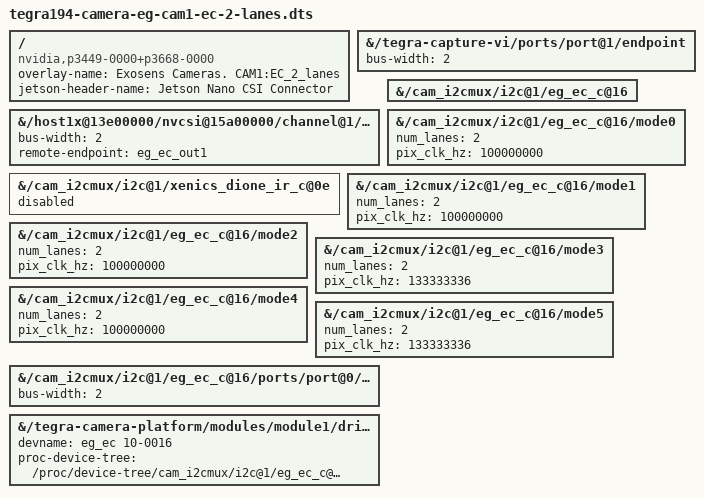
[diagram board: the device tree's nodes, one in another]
// SPDX-License-Identifier: GPL-2.0-only


/dts-v1/;
/plugin/;

/ {
	overlay-name = "Exosens Cameras. CAM1:EC_2_lanes";
	jetson-header-name = "Jetson Nano CSI Connector";
	compatible = "nvidia,p3449-0000+p3668-0000", "nvidia,p3449-0000+p3668-0001", "nvidia,p3509-0000+p3668-0000", "nvidia,p3509-0000+p3668-0001";

	fragment@10 {
		target-path = "/tegra-capture-vi/ports/port@1/endpoint";
		__overlay__ {
			bus-width=<2>;
		};
	};

	fragment@11 {
		target-path = "/host1x@13e00000/nvcsi@15a00000/channel@1/ports/port@0/endpoint@2";
		__overlay__ {
			bus-width=<2>;
         remote-endpoint = <&eg_ec_out1>;
		};
	};

   // Disable Dione cameras
	fragment@12 {
		target-path = "/cam_i2cmux/i2c@1/xenics_dione_ir_c@0e";
		__overlay__ {
         status = "disabled";
		};
	};

   // Enable EngineCore cameras
	fragment@13 {
		target-path = "/cam_i2cmux/i2c@1/eg_ec_c@16";
		__overlay__ {
         status = "okay";
		};
	};
	fragment@14 {   
		target-path = "/cam_i2cmux/i2c@1/eg_ec_c@16/mode0";
		__overlay__ {
         num_lanes = "2";
         pix_clk_hz = "100000000";
		};
	};
	fragment@15 {
		target-path = "/cam_i2cmux/i2c@1/eg_ec_c@16/mode1";
		__overlay__ {
         num_lanes = "2";
         pix_clk_hz = "100000000";
		};
	};
	fragment@16 {
		target-path = "/cam_i2cmux/i2c@1/eg_ec_c@16/mode2";
		__overlay__ {
         num_lanes = "2";
         pix_clk_hz = "100000000";
		};
	};
	fragment@17 {
		target-path = "/cam_i2cmux/i2c@1/eg_ec_c@16/mode3";
		__overlay__ {
         num_lanes = "2";
         pix_clk_hz = "133333336";
		};
	};
	fragment@18 {
		target-path = "/cam_i2cmux/i2c@1/eg_ec_c@16/mode4";
		__overlay__ {
         num_lanes = "2";
         pix_clk_hz = "100000000";
		};
	};
	fragment@19 {
		target-path = "/cam_i2cmux/i2c@1/eg_ec_c@16/mode5";
		__overlay__ {
         num_lanes = "2";
         pix_clk_hz = "133333336";
		};
	};
	fragment@20 {
		target-path = "/cam_i2cmux/i2c@1/eg_ec_c@16/ports/port@0/endpoint";
		__overlay__ {
			bus-width=<2>;
		};
	};

	fragment@21 {
		target-path = "/tegra-camera-platform/modules/module1/drivernode0";
		__overlay__ {
         devname = "eg_ec 10-0016";
			proc-device-tree = "/proc/device-tree/cam_i2cmux/i2c@1/eg_ec_c@16";
		};
	};


};
